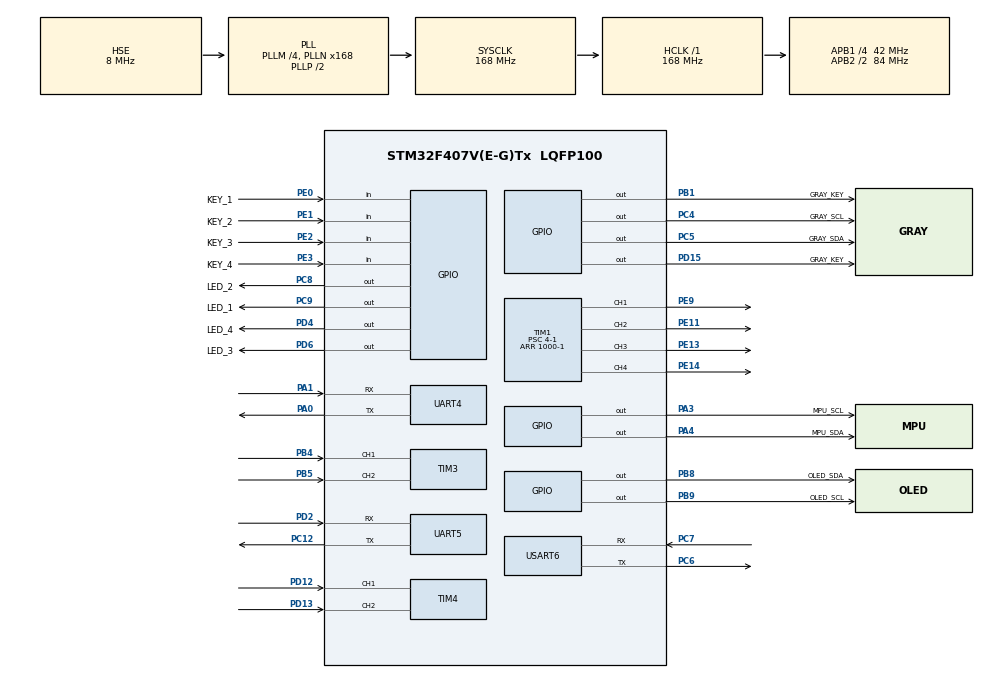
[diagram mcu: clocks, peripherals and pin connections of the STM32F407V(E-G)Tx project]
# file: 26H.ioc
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Dma.Request0=UART4_RX
Dma.Request1=UART4_TX
Dma.UART4_RX.0.Direction=DMA_PERIPH_TO_MEMORY
Dma.UART4_RX.0.FIFOMode=DMA_FIFOMODE_DISABLE
Dma.UART4_RX.0.Instance=DMA1_Stream2
Dma.UART4_RX.0.MemDataAlignment=DMA_MDATAALIGN_BYTE
Dma.UART4_RX.0.MemInc=DMA_MINC_ENABLE
Dma.UART4_RX.0.Mode=DMA_NORMAL
Dma.UART4_RX.0.PeriphDataAlignment=DMA_PDATAALIGN_BYTE
Dma.UART4_RX.0.PeriphInc=DMA_PINC_DISABLE
Dma.UART4_RX.0.Priority=DMA_PRIORITY_LOW
Dma.UART4_TX.1.Direction=DMA_MEMORY_TO_PERIPH
Dma.UART4_TX.1.FIFOMode=DMA_FIFOMODE_DISABLE
Dma.UART4_TX.1.Instance=DMA1_Stream4
Dma.UART4_TX.1.MemDataAlignment=DMA_MDATAALIGN_BYTE
Dma.UART4_TX.1.MemInc=DMA_MINC_ENABLE
Dma.UART4_TX.1.Mode=DMA_NORMAL
Dma.UART4_TX.1.PeriphDataAlignment=DMA_PDATAALIGN_BYTE
Dma.UART4_TX.1.PeriphInc=DMA_PINC_DISABLE
Dma.UART4_TX.1.Priority=DMA_PRIORITY_LOW
FREERTOS.Tasks01=GrayTrackTask,40,256,StartGrayTrackTask,As external,NULL,Dynamic,NULL,NULL;DisplayTask,8,384,StartDisplayTask,As external,NULL,Dynamic,NULL,NULL;TubeTask,32,384,StartTubeTask,As external,NULL,Dynamic,NULL,NULL
Mcu.Family=STM32F4
Mcu.Name=STM32F407V(E-G)Tx
Mcu.Package=LQFP100
NVIC.DMA1_Stream2_IRQn=true\:5\:0\:false\:false\:true\:true\:false\:true\:true
NVIC.DMA1_Stream4_IRQn=true\:5\:0\:false\:false\:true\:true\:false\:true\:true
NVIC.PriorityGroup=NVIC_PRIORITYGROUP_4
NVIC.TIM6_DAC_IRQn=true\:15\:0\:false\:false\:true\:false\:false\:true\:true
NVIC.TimeBase=TIM6_DAC_IRQn
NVIC.TimeBaseIP=TIM6
NVIC.UART4_IRQn=true\:5\:0\:false\:false\:true\:true\:true\:true\:true
NVIC.UART5_IRQn=true\:5\:0\:false\:false\:true\:true\:true\:true\:true
NVIC.USART6_IRQn=true\:5\:0\:false\:false\:true\:true\:true\:true\:true
PA0-WKUP.Mode=Asynchronous
PA0-WKUP.Signal=UART4_TX
PA1.Mode=Asynchronous
PA1.Signal=UART4_RX
PA13.Mode=Serial_Wire
PA13.Signal=SYS_JTMS-SWDIO
PA14.Mode=Serial_Wire
PA14.Signal=SYS_JTCK-SWCLK
PA3.GPIO_Label=MPU_SCL
PA3.GPIO_ModeDefaultOutputPP=GPIO_MODE_OUTPUT_OD
PA3.GPIO_PuPd=GPIO_PULLUP
PA3.GPIO_Speed=GPIO_SPEED_FREQ_VERY_HIGH
PA3.PinState=GPIO_PIN_SET
PA3.Signal=GPIO_Output
PA4.GPIO_Label=MPU_SDA
PA4.GPIO_ModeDefaultOutputPP=GPIO_MODE_OUTPUT_OD
PA4.GPIO_PuPd=GPIO_PULLUP
PA4.GPIO_Speed=GPIO_SPEED_FREQ_VERY_HIGH
PA4.PinState=GPIO_PIN_SET
PA4.Signal=GPIO_Output
PB1.GPIO_Label=GRAY_KEY
PB1.GPIO_ModeDefaultOutputPP=GPIO_MODE_OUTPUT_OD
PB1.GPIO_PuPd=GPIO_PULLUP
PB1.PinState=GPIO_PIN_SET
PB1.Signal=GPIO_Output
PB4.GPIO_Speed=GPIO_SPEED_FREQ_VERY_HIGH
PB4.Signal=S_TIM3_CH1
PB5.GPIO_Speed=GPIO_SPEED_FREQ_VERY_HIGH
PB5.Signal=S_TIM3_CH2
PB8.GPIO_Label=OLED_SDA
PB8.GPIO_ModeDefaultOutputPP=GPIO_MODE_OUTPUT_OD
PB8.GPIO_PuPd=GPIO_PULLUP
PB8.GPIO_Speed=GPIO_SPEED_FREQ_VERY_HIGH
PB8.PinState=GPIO_PIN_SET
PB8.Signal=GPIO_Output
PB9.GPIO_Label=OLED_SCL
PB9.GPIO_ModeDefaultOutputPP=GPIO_MODE_OUTPUT_OD
PB9.GPIO_PuPd=GPIO_PULLUP
PB9.GPIO_Speed=GPIO_SPEED_FREQ_VERY_HIGH
PB9.PinState=GPIO_PIN_SET
PB9.Signal=GPIO_Output
PC12.Mode=Asynchronous
PC12.Signal=UART5_TX
PC4.GPIO_Label=GRAY_SCL
PC4.GPIO_ModeDefaultOutputPP=GPIO_MODE_OUTPUT_OD
PC4.GPIO_PuPd=GPIO_PULLUP
PC4.GPIO_Speed=GPIO_SPEED_FREQ_LOW
PC4.PinState=GPIO_PIN_SET
PC4.Signal=GPIO_Output
PC5.GPIO_Label=GRAY_SDA
PC5.GPIO_ModeDefaultOutputPP=GPIO_MODE_OUTPUT_OD
PC5.GPIO_PuPd=GPIO_PULLUP
PC5.GPIO_Speed=GPIO_SPEED_FREQ_LOW
PC5.PinState=GPIO_PIN_SET
PC5.Signal=GPIO_Output
PC6.Mode=Asynchronous
PC6.Signal=USART6_TX
PC7.Mode=Asynchronous
PC7.Signal=USART6_RX
PC8.GPIO_Label=LED_2
PC8.GPIO_ModeDefaultOutputPP=GPIO_MODE_OUTPUT_OD
PC8.GPIO_PuPd=GPIO_PULLUP
PC8.PinState=GPIO_PIN_SET
PC8.Signal=GPIO_Output
PC9.GPIO_Label=LED_1
PC9.GPIO_ModeDefaultOutputPP=GPIO_MODE_OUTPUT_OD
PC9.GPIO_PuPd=GPIO_PULLUP
PC9.PinState=GPIO_PIN_SET
PC9.Signal=GPIO_Output
PD12.GPIO_Speed=GPIO_SPEED_FREQ_VERY_HIGH
PD12.Signal=S_TIM4_CH1
PD13.GPIO_Speed=GPIO_SPEED_FREQ_VERY_HIGH
PD13.Signal=S_TIM4_CH2
PD15.GPIO_Label=GRAY_KEY
PD15.GPIO_ModeDefaultOutputPP=GPIO_MODE_OUTPUT_OD
PD15.GPIO_PuPd=GPIO_PULLUP
PD15.GPIO_Speed=GPIO_SPEED_FREQ_VERY_HIGH
PD15.PinState=GPIO_PIN_SET
PD15.Signal=GPIO_Output
PD2.Mode=Asynchronous
PD2.Signal=UART5_RX
PD4.GPIO_Label=LED_4
PD4.GPIO_ModeDefaultOutputPP=GPIO_MODE_OUTPUT_OD
PD4.GPIO_PuPd=GPIO_PULLUP
PD4.PinState=GPIO_PIN_SET
PD4.Signal=GPIO_Output
PD6.GPIO_Label=LED_3
PD6.GPIO_ModeDefaultOutputPP=GPIO_MODE_OUTPUT_OD
PD6.GPIO_PuPd=GPIO_PULLUP
PD6.PinState=GPIO_PIN_SET
PD6.Signal=GPIO_Output
PE0.GPIO_Label=KEY_1
PE0.GPIO_Mode=GPIO_MODE_INPUT
PE0.GPIO_PuPd=GPIO_PULLUP
PE0.Signal=GPIO_Input
PE1.GPIO_Label=KEY_2
PE1.GPIO_Mode=GPIO_MODE_INPUT
PE1.GPIO_PuPd=GPIO_PULLUP
PE1.Signal=GPIO_Input
PE11.GPIO_Speed=GPIO_SPEED_FREQ_VERY_HIGH
PE11.Signal=S_TIM1_CH2
PE13.GPIO_Speed=GPIO_SPEED_FREQ_VERY_HIGH
PE13.Signal=S_TIM1_CH3
PE14.GPIO_Speed=GPIO_SPEED_FREQ_VERY_HIGH
PE14.Signal=S_TIM1_CH4
PE2.GPIO_Label=KEY_3
PE2.GPIO_Mode=GPIO_MODE_INPUT
PE2.GPIO_PuPd=GPIO_PULLUP
PE2.Signal=GPIO_Input
PE3.GPIO_Label=KEY_4
PE3.GPIO_Mode=GPIO_MODE_INPUT
PE3.GPIO_PuPd=GPIO_PULLUP
PE3.Signal=GPIO_Input
PE9.GPIO_Speed=GPIO_SPEED_FREQ_VERY_HIGH
PE9.Signal=S_TIM1_CH1
PH0-OSC_IN.Mode=HSE-External-Oscillator
PH0-OSC_IN.Signal=RCC_OSC_IN
PH1-OSC_OUT.Mode=HSE-External-Oscillator
PH1-OSC_OUT.Signal=RCC_OSC_OUT
ProjectManager.HeapSize=0x200
ProjectManager.StackSize=0x400
ProjectManager.TargetToolchain=MDK-ARM V5.32
RCC.48MHZClocksFreq_Value=84000000
RCC.AHBFreq_Value=168000000
RCC.APB1CLKDivider=RCC_HCLK_DIV4
RCC.APB1Freq_Value=42000000
RCC.APB1TimFreq_Value=84000000
RCC.APB2CLKDivider=RCC_HCLK_DIV2
RCC.APB2Freq_Value=84000000
RCC.APB2TimFreq_Value=168000000
RCC.CortexFreq_Value=168000000
RCC.HCLKFreq_Value=168000000
RCC.HSE_VALUE=8000000
RCC.HSI_VALUE=16000000
RCC.LSE_VALUE=32768
RCC.PLLM=4
RCC.PLLN=168
RCC.PLLSourceVirtual=RCC_PLLSOURCE_HSE
RCC.SYSCLKFreq_VALUE=168000000
RCC.SYSCLKSource=RCC_SYSCLKSOURCE_PLLCLK
RCC.VCOOutputFreq_Value=336000000
SH.S_TIM1_CH1.0=TIM1_CH1,PWM Generation1 CH1
SH.S_TIM1_CH2.0=TIM1_CH2,PWM Generation2 CH2
SH.S_TIM1_CH3.0=TIM1_CH3,PWM Generation3 CH3
SH.S_TIM1_CH4.0=TIM1_CH4,PWM Generation4 CH4
SH.S_TIM3_CH1.0=TIM3_CH1,Encoder_Interface
SH.S_TIM3_CH2.0=TIM3_CH2,Encoder_Interface
SH.S_TIM4_CH1.0=TIM4_CH1,Encoder_Interface
SH.S_TIM4_CH2.0=TIM4_CH2,Encoder_Interface
TIM1.Channel-PWM\ Generation1\ CH1=TIM_CHANNEL_1
TIM1.Channel-PWM\ Generation2\ CH2=TIM_CHANNEL_2
TIM1.Channel-PWM\ Generation3\ CH3=TIM_CHANNEL_3
TIM1.Channel-PWM\ Generation4\ CH4=TIM_CHANNEL_4
TIM1.Period=1000-1
TIM1.Prescaler=4-1
TIM3.EncoderMode=TIM_ENCODERMODE_TI12
TIM4.EncoderMode=TIM_ENCODERMODE_TI12
UART4.VirtualMode=Asynchronous
UART5.VirtualMode=Asynchronous
USART6.VirtualMode=VM_ASYNC
VP_FREERTOS_VS_CMSIS_V2.Mode=CMSIS_V2
VP_SYS_VS_tim6.Mode=TIM6
board=custom

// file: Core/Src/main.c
/* USER CODE BEGIN Header */
/**
  ******************************************************************************
  * @file           : main.c
  * @brief          : Main program body
  ******************************************************************************
  * @attention
  *
  * Copyright (c) 2026 STMicroelectronics.
  * All rights reserved.
  *
  * This software is licensed under terms that can be found in the LICENSE file
  * in the root directory of this software component.
  * If no LICENSE file comes with this software, it is provided AS-IS.
  *
  ******************************************************************************
  */
/* USER CODE END Header */
#include "main.h"
#include "cmsis_os.h"
#include "dma.h"
#include "tim.h"
#include "usart.h"
#include "gpio.h"

void SystemClock_Config(void);
void MX_FREERTOS_Init(void);

int main(void)
{

  /* MCU Configuration--------------------------------------------------------*/

  /* Reset of all peripherals, Initializes the Flash interface and the Systick. */
  HAL_Init();

  /* Configure the system clock */
  SystemClock_Config();

  /* Initialize all configured peripherals */
  MX_GPIO_Init();
  MX_DMA_Init();
  MX_TIM1_Init();
  MX_TIM3_Init();
  MX_TIM4_Init();
  MX_UART4_Init();
  MX_UART5_Init();
  MX_USART6_UART_Init();

  /* Init scheduler */
  osKernelInitialize();  /* Call init function for freertos objects (in cmsis_os2.c) */
  MX_FREERTOS_Init();

  /* Start scheduler */
  osKernelStart();

  /* We should never get here as control is now taken by the scheduler */

  /* Infinite loop */
  while (1)
  {

  }
}

void SystemClock_Config(void)
{
  RCC_OscInitTypeDef RCC_OscInitStruct = {0};
  RCC_ClkInitTypeDef RCC_ClkInitStruct = {0};

  /** Configure the main internal regulator output voltage
  */
  __HAL_RCC_PWR_CLK_ENABLE();
  __HAL_PWR_VOLTAGESCALING_CONFIG(PWR_REGULATOR_VOLTAGE_SCALE1);

  /** Initializes the RCC Oscillators according to the specified parameters
  * in the RCC_OscInitTypeDef structure.
  */
  RCC_OscInitStruct.OscillatorType = RCC_OSCILLATORTYPE_HSE;
  RCC_OscInitStruct.HSEState = RCC_HSE_ON;
  RCC_OscInitStruct.PLL.PLLState = RCC_PLL_ON;
  RCC_OscInitStruct.PLL.PLLSource = RCC_PLLSOURCE_HSE;
  RCC_OscInitStruct.PLL.PLLM = 4;
  RCC_OscInitStruct.PLL.PLLN = 168;
  RCC_OscInitStruct.PLL.PLLP = RCC_PLLP_DIV2;
  RCC_OscInitStruct.PLL.PLLQ = 4;
  if (HAL_RCC_OscConfig(&RCC_OscInitStruct) != HAL_OK)
  {
    Error_Handler();
  }

  /** Initializes the CPU, AHB and APB buses clocks
  */
  RCC_ClkInitStruct.ClockType = RCC_CLOCKTYPE_HCLK|RCC_CLOCKTYPE_SYSCLK
                              |RCC_CLOCKTYPE_PCLK1|RCC_CLOCKTYPE_PCLK2;
  RCC_ClkInitStruct.SYSCLKSource = RCC_SYSCLKSOURCE_PLLCLK;
  RCC_ClkInitStruct.AHBCLKDivider = RCC_SYSCLK_DIV1;
  RCC_ClkInitStruct.APB1CLKDivider = RCC_HCLK_DIV4;
  RCC_ClkInitStruct.APB2CLKDivider = RCC_HCLK_DIV2;

  if (HAL_RCC_ClockConfig(&RCC_ClkInitStruct, FLASH_LATENCY_5) != HAL_OK)
  {
    Error_Handler();
  }
}

void HAL_TIM_PeriodElapsedCallback(TIM_HandleTypeDef *htim)
{
  if (htim->Instance == TIM6)
  {
    HAL_IncTick();
  }
}

void Error_Handler(void)
{
  __disable_irq();
  while (1)
  {
  }
}

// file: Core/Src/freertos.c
/* USER CODE BEGIN Header */
/**
  ******************************************************************************
  * File Name          : freertos.c
  * Description        : Code for freertos applications
  ******************************************************************************
  * @attention
  *
  * Copyright (c) 2026 STMicroelectronics.
  * All rights reserved.
  *
  * This software is licensed under terms that can be found in the LICENSE file
  * in the root directory of this software component.
  * If no LICENSE file comes with this software, it is provided AS-IS.
  *
  ******************************************************************************
  */
/* USER CODE END Header */

#include "FreeRTOS.h"
#include "task.h"
#include "main.h"
#include "cmsis_os.h"

/* USER CODE BEGIN Includes */
#include "OLED.h"
#include "mpu6050.h"
#include "LineSensor.h"
/* USER CODE END Includes */

/* Definitions for GrayTrackTask */
osThreadId_t GrayTrackTaskHandle;
const osThreadAttr_t GrayTrackTask_attributes = {
  .name = "GrayTrackTask",
  .stack_size = 256 * 4,
  .priority = (osPriority_t) osPriorityHigh,
};
/* Definitions for DisplayTask */
osThreadId_t DisplayTaskHandle;
const osThreadAttr_t DisplayTask_attributes = {
  .name = "DisplayTask",
  .stack_size = 384 * 4,
  .priority = (osPriority_t) osPriorityLow,
};
/* Definitions for TubeTask */
osThreadId_t TubeTaskHandle;
const osThreadAttr_t TubeTask_attributes = {
  .name = "TubeTask",
  .stack_size = 384 * 4,
  .priority = (osPriority_t) osPriorityAboveNormal,
};

extern void StartGrayTrackTask(void *argument);
extern void StartDisplayTask(void *argument);
extern void StartTubeTask(void *argument);

void MX_FREERTOS_Init(void); /* (MISRA C 2004 rule 8.1) */

void MX_FREERTOS_Init(void) {
  /* USER CODE BEGIN Init */
  HAL_Delay(500);
  OLED_Init();

  // MPU6050_Init(&imu);
  // MPU6050_CalibrateGyro(&imu,500);

  /* USER CODE END Init */

  /* Create the thread(s) */
  /* creation of GrayTrackTask */
  GrayTrackTaskHandle = osThreadNew(StartGrayTrackTask, NULL, &GrayTrackTask_attributes);

  /* creation of DisplayTask */
  DisplayTaskHandle = osThreadNew(StartDisplayTask, NULL, &DisplayTask_attributes);

  /* creation of TubeTask */
  TubeTaskHandle = osThreadNew(StartTubeTask, NULL, &TubeTask_attributes);

}

__weak void StartGrayTrackTask(void *argument)
{
  for(;;)
  {
    osDelay(1);
  }
}
